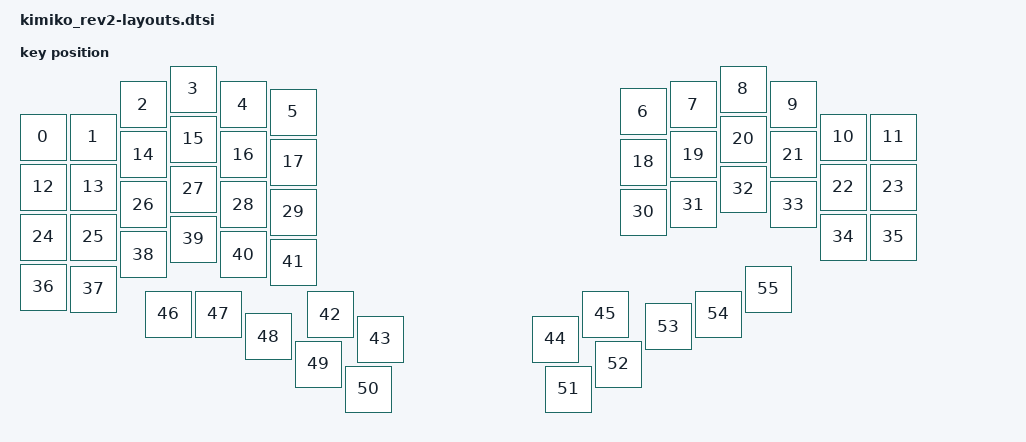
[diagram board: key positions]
#include <physical_layouts.dtsi>

/ {
    keycapsss_kimiko_layout: keycapsss_kimiko_layout {
        compatible = "zmk,physical-layout";
        display-name = "Kimiko Rev2";

      keys  //                     w   h    x    y     rot    rx    ry
        = <&key_physical_attrs 100 100 0 96 0 0 0>
        , <&key_physical_attrs 100 100 100 96 0 0 0>
        , <&key_physical_attrs 100 100 200 31 0 0 0>
        , <&key_physical_attrs 100 100 300    0 0 0 0>
        , <&key_physical_attrs 100 100 400 31 0 0 0>
        , <&key_physical_attrs 100 100 500 46 0 0 0>
        , <&key_physical_attrs 100 100 1200 45 0 0 0>
        , <&key_physical_attrs 100 100 1300 31 0 0 0>
        , <&key_physical_attrs 100 100 1400    0 0 0 0>
        , <&key_physical_attrs 100 100 1500 31 0 0 0>
        , <&key_physical_attrs 100 100 1600 96 0 0 0>
        , <&key_physical_attrs 100 100 1700 96 0 0 0>
        , <&key_physical_attrs 100 100 0 196 0 0 0>
        , <&key_physical_attrs 100 100 100 196 0 0 0>
        , <&key_physical_attrs 100 100 200 131 0 0 0>
        , <&key_physical_attrs 100 100 300    100 0 0 0>
        , <&key_physical_attrs 100 100 400 131 0 0 0>
        , <&key_physical_attrs 100 100 500 146 0 0 0>
        , <&key_physical_attrs 100 100 1200 146 0 0 0>
        , <&key_physical_attrs 100 100 1300 131 0 0 0>
        , <&key_physical_attrs 100 100 1400    100 0 0 0>
        , <&key_physical_attrs 100 100 1500 131 0 0 0>
        , <&key_physical_attrs 100 100 1600 196 0 0 0>
        , <&key_physical_attrs 100 100 1700 196 0 0 0>
        , <&key_physical_attrs 100 100 0 296 0 0 0>
        , <&key_physical_attrs 100 100 100 296 0 0 0>
        , <&key_physical_attrs 100 100 200 231 0 0 0>
        , <&key_physical_attrs 100 100 300    200 0 0 0>
        , <&key_physical_attrs 100 100 400 231 0 0 0>
        , <&key_physical_attrs 100 100 500 246 0 0 0>
        , <&key_physical_attrs 100 100 1200 246 0 0 0>
        , <&key_physical_attrs 100 100 1300 231 0 0 0>
        , <&key_physical_attrs 100 100 1400    200 0 0 0>
        , <&key_physical_attrs 100 100 1500 231 0 0 0>
        , <&key_physical_attrs 100 100 1600 296 0 0 0>
        , <&key_physical_attrs 100 100 1700 296 0 0 0>
        , <&key_physical_attrs 100 100 0 396 0 0 0>
        , <&key_physical_attrs 100 100 100    400 0 0 0>
        , <&key_physical_attrs 100 100 200 331 0 0 0>
        , <&key_physical_attrs 100 100 300    300 0 0 0>
        , <&key_physical_attrs 100 100 400 331 0 0 0>
        , <&key_physical_attrs 100 100 500 346 0 0 0>
        , <&key_physical_attrs 100 100 575 451 0 0 0>
        , <&key_physical_attrs 100 100 675    500 0 0 0>
        , <&key_physical_attrs 100 100 1025    500 0 0 0>
        , <&key_physical_attrs 100 100 1125  450 0 0 0>
        , <&key_physical_attrs 100 100 120 346> 0 0 0 
        , <&key_physical_attrs 100 100 130 331> 0 0 0 
        , <&key_physical_attrs 100 100 140     300> 0 0 0 
        , <&key_physical_attrs 100 100 150 331> 0 0 0 
        , <&key_physical_attrs 100 100 160 396> 0 0 0 
        , <&key_physical_attrs 100 100 170  396> 0 0 0 
        , <&key_physical_attrs 100 100 250  450 0 0 0>
        , <&key_physical_attrs 100 100 350  450 0 0 0>
        , <&key_physical_attrs 100 100 450 495 0 0 0>
        , <&key_physical_attrs 100 100 550  550 0 0 0>
        , <&key_physical_attrs 100 100 650    600 0 0 0>
        , <&key_physical_attrs 100 100 1050    600 0 0 0>
        , <&key_physical_attrs 100 100 1150  550 0 0 0>
        , <&key_physical_attrs 100 100 1250 475 0 0 0>
        , <&key_physical_attrs 100 100 1350  450 0 0 0>
        , <&key_physical_attrs 100 100 1450  400 0 0 0>
      ;
    };
};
